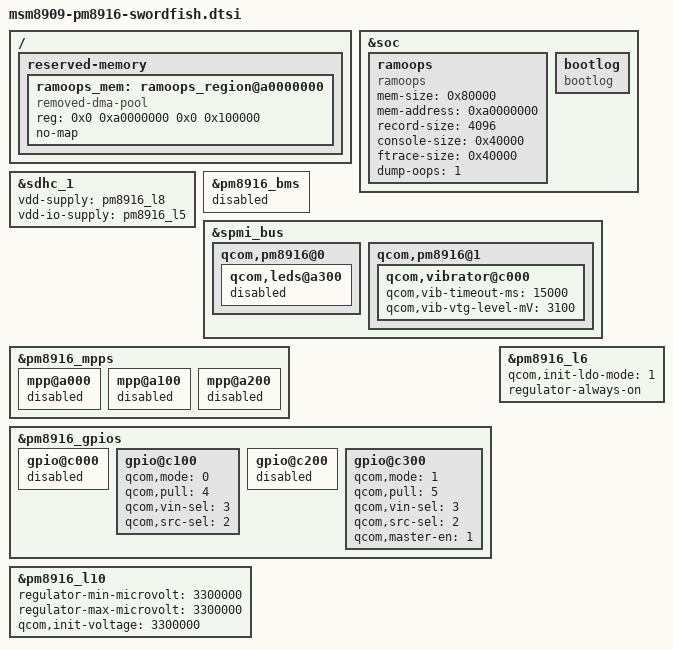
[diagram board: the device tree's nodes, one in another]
/* Copyright (c) 2016, LGE Inc. All rights reserved.
 *
 * This program is free software; you can redistribute it and/or modify
 * it under the terms of the GNU General Public License version 2 and
 * only version 2 as published by the Free Software Foundation.
 *
 * This program is distributed in the hope that it will be useful,
 * but WITHOUT ANY WARRANTY; without even the implied warranty of
 * MERCHANTABILITY or FITNESS FOR A PARTICULAR PURPOSE.  See the
 * GNU General Public License for more details.
 */

#include "msm8909-swordfish-pm.dtsi"

/ {
	reserved-memory {
    	ramoops_mem: ramoops_region@a0000000 {
			reg = <0x0 0xa0000000 0x0 0x100000>;
	        compatible = "removed-dma-pool";
	        no-map;
	    };
	};
};

&soc {
	ramoops {
		compatible = "ramoops";
		mem-size = <0x80000>;
		mem-address = <0xa0000000>;
		record-size = <4096>;
		console-size = <0x40000>;
		ftrace-size = <0x40000>;
		dump-oops = <1>;
	};

	bootlog {
		compatible = "bootlog";
	};

};

&sdhc_1 {
	vdd-supply = <&pm8916_l8>;
	vdd-io-supply = <&pm8916_l5>;
};

&pm8916_bms {
	status = "disabled";
};

&spmi_bus {
	qcom,pm8916@0 {
		qcom,leds@a300 {
			status = "disabled";
		};
	};

	qcom,pm8916@1 {
		qcom,vibrator@c000 {
			status = "okay";
			qcom,vib-timeout-ms = <15000>;
			qcom,vib-vtg-level-mV = <3100>;
		};
	};
};

&pm8916_mpps {
	mpp@a000 { /* MPP 1 */
		/* VDD_PX */
		status = "disabled";
	};

	mpp@a100 { /* MPP 2 */
		/* HR LED */
		status = "disabled";
	};

	mpp@a200 { /* MPP 3 */
		/* VREF DAC */
		status = "disabled";
	};
};

&pm8916_gpios {
	gpio@c000 { /* GPIO 1 */
		/* Battery UICC Alarm */
		status = "disabled";
	};

	gpio@c100 { /* GPIO 2 */
		/* NFC_CLK_REQ */
		qcom,mode = <0>; /* QPNP_PIN_MODE_DIG_IN */
		qcom,pull = <4>; /* QPNP_PIN_PULL_DN - Not Fixed */
		qcom,vin-sel = <3>; /* QPNP_PIN_VIN2 */
		qcom,src-sel = <2>; /* QPNP_PIN_SEL_FUNC_1 */
	};

	gpio@c200 { /* GPIO 3 */
		/* External regulator control for WTR */
		status = "disabled";
	};

	gpio@c300 { /* GPIO 4 */
		/* alternative sleep_clk for sensor hub */
		qcom,mode = <1>;    /* QPNP_PIN_MODE_DIG_OUT */
		qcom,pull = <5>;    /* QPNP_PIN_GPIO_PULL_NO */
		qcom,vin-sel = <3>; /* QPNP_PIN_VIN3(VREG_L5)*/
		qcom,src-sel = <2>; /* SPECIAL_FUNC_1(0x4) */
		qcom,master-en = <1>;
	};
};

&pm8916_l6 {
	qcom,init-ldo-mode = <1>; /* NPM */
	regulator-always-on; /* Always on for sensor hub */
};

&pm8916_l10 {
	regulator-min-microvolt = <3300000>;
	regulator-max-microvolt = <3300000>;
	qcom,init-voltage = <3300000>;
	status = "okay";
};
